# USB0_RAMS_INJ_CFG register map
Vendor: Texas Instruments
Peripheral module from a debugger description file (folder J7VCL).
Registers are 32-bit, read-only, reset 0x0 unless marked. A register's access mark holds for its fields unless they carry their own. Offsets are as the file gives them; lines under a group give offsets from that group; [hi:lo] are bit positions; {n}, {i} and the like mark numbered series; 'fields as' and 'values as' point back to an identical list; <NAME> marks a mode.

## USB0_RAMS_INJ_CFG
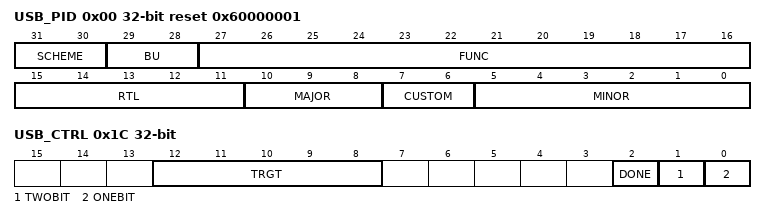
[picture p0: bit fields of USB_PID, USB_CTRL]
0x00 USB_PID reset 0x60000001 — The Revision Register contains the major and minor revisions for the module.
  [31:30] SCHEME
  [29:28] BU
  [27:16] FUNC — Module ID
  [15:11] RTL — RTL revision.
  [10:8] MAJOR — Major revision
  [7:6] CUSTOM
  [5:0] MINOR — Minor revision
0x04 USB_INFO reset 0x1E — The Info Register gives the configuration Inforrmation of this module.
  [5:0] ENDPOINTS — Total number of Targets supported by this configuration
0x08 USB_SFT_RST wo — The Global Soft Reset Register clears all programmable registers and returns the injector to idle state
  [3:0] KEY — Write 4'b1010 to issue a soft reset.
0x10 USB_BIT1 rw — This register defines the first bit to be flipped when injection is enabled
  [15:0] BIT1 — First bit to be flipped on an error injection
0x14 USB_BIT2 rw — This register defines the second bit to be flipped if 2-bit injection is enabled
  [15:0] BIT2 — Second bit to be flipped on an error injection if 2-bit injection is chosen.
0x18 USB_TRGT rw — This is the target selection register
  [4:0] TRGT — Select which target to interact with.
0x1C USB_CTRL access per field — Controls the injection
  [12:8] TRGT ro — Indicates which target is selected by the
  [2] DONE ro — Indicates that the target selected by
  [1] TWOBIT rw — Write 1 to trigger a 2-bit error in target selected by
  [0] ONEBIT rw — Write 1 to trigger a 1-bit error in target selected by
0x20 USB_STATUS — Controls the injection
  [2] ARMED — Indicates that the target selected by
